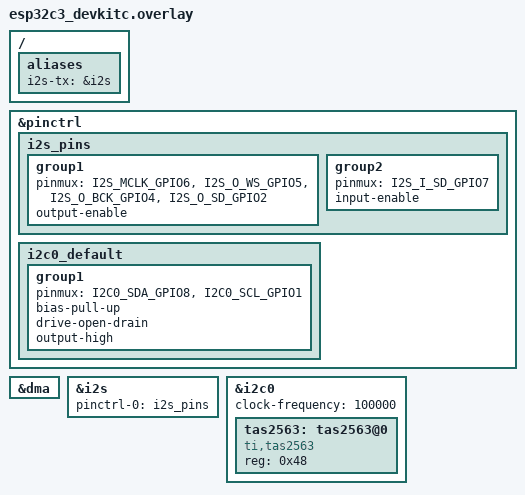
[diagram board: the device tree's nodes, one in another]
/*
 * Copyright (c) 2025 Espressif Systems (Shanghai) Co., Ltd.
 *
 * SPDX-License-Identifier: Apache-2.0
 */


 / {
	aliases {
		i2s-tx = &i2s;
	};
};

&pinctrl {
	i2s_pins: i2s_pins {
		group1 {
			pinmux = <I2S_MCLK_GPIO6>,
				 <I2S_O_WS_GPIO5>,
				 <I2S_O_BCK_GPIO4>,
				 <I2S_O_SD_GPIO2>;
			output-enable;
		};
		group2 {
			pinmux = <I2S_I_SD_GPIO7>;
			input-enable;
		};
	};
	i2c0_default: i2c0_default {
		group1 {
			pinmux = <I2C0_SDA_GPIO8>,
				 <I2C0_SCL_GPIO1>;
			bias-pull-up;
			drive-open-drain;
			output-high;
		};
	};
};

&dma {
	status = "okay";
};

&i2s {
	status = "okay";
	pinctrl-0 = <&i2s_pins>;
	pinctrl-names = "default";
};

&i2c0 {
	status = "okay";
	clock-frequency = <100000>;

	// tas6422dac: tas6422dac@0 {
	// 	compatible = "ti,tas6422dac";
	// 	status = "okay";
	// 	reg = <0x0>;
	// };

	tas2563: tas2563@0 {
		compatible = "ti,tas2563";
		status = "okay";
		reg = <0x48>;
	};
};
